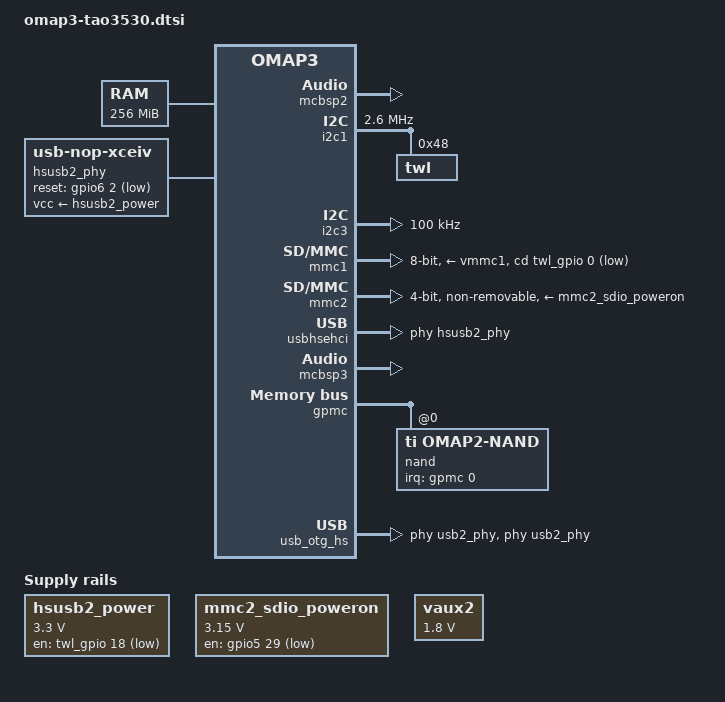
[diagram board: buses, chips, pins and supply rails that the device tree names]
/dts-v1/;
#include "omap34xx.dtsi"
&aes1_target {
	status = "disabled";
};
&aes2_target {
	status = "disabled";
};
&sham {
	status = "disabled";
};
/ {
	cpus {
		cpu@0 {
			cpu0-supply = <&vcc>;
		};
	};
	memory@80000000 {
		device_type = "memory";
		reg = <0x80000000 0x10000000>;  
	};
	hsusb2_power: hsusb2_power_reg {
		compatible = "regulator-fixed";
		regulator-name = "hsusb2_vbus";
		regulator-min-microvolt = <3300000>;
		regulator-max-microvolt = <3300000>;
		gpio = <&twl_gpio 18 GPIO_ACTIVE_HIGH>;	 
		startup-delay-us = <70000>;
	};
	hsusb2_phy: hsusb2-phy-pins {
		compatible = "usb-nop-xceiv";
		reset-gpios = <&gpio6 2 GPIO_ACTIVE_LOW>;	 
		vcc-supply = <&hsusb2_power>;
		#phy-cells = <0>;
	};
	sound {
		compatible = "ti,omap-twl4030";
		ti,model = "omap3beagle";
		ti,mcbsp = <&mcbsp2>;
	};
	mmc2_sdio_poweron: regulator-mmc2-sdio-poweron {
		compatible = "regulator-fixed";
		regulator-name = "regulator-mmc2-sdio-poweron";
		regulator-min-microvolt = <3150000>;
		regulator-max-microvolt = <3150000>;
		gpio = <&gpio5 29 GPIO_ACTIVE_LOW>;		 
		startup-delay-us = <10000>;
	};
};
&omap3_pmx_core {
	hsusbb2_pins: hsusbb2-pins {
		pinctrl-single,pins = <
			OMAP3_CORE1_IOPAD(0x25f0, PIN_OUTPUT | MUX_MODE3)		 
			OMAP3_CORE1_IOPAD(0x25f2, PIN_OUTPUT | MUX_MODE3)		 
			OMAP3_CORE1_IOPAD(0x25f4, PIN_INPUT_PULLDOWN | MUX_MODE3)	 
			OMAP3_CORE1_IOPAD(0x25f6, PIN_INPUT_PULLDOWN | MUX_MODE3)	 
			OMAP3_CORE1_IOPAD(0x25f8, PIN_INPUT_PULLDOWN | MUX_MODE3)	 
			OMAP3_CORE1_IOPAD(0x25fa, PIN_INPUT_PULLDOWN | MUX_MODE3)	 
			OMAP3_CORE1_IOPAD(0x21d4, PIN_INPUT_PULLDOWN | MUX_MODE3)	 
			OMAP3_CORE1_IOPAD(0x21d6, PIN_INPUT_PULLDOWN | MUX_MODE3)	 
			OMAP3_CORE1_IOPAD(0x21d8, PIN_INPUT_PULLDOWN | MUX_MODE3)	 
			OMAP3_CORE1_IOPAD(0x21da, PIN_INPUT_PULLDOWN | MUX_MODE3)	 
			OMAP3_CORE1_IOPAD(0x21dc, PIN_INPUT_PULLDOWN | MUX_MODE3)	 
			OMAP3_CORE1_IOPAD(0x21de, PIN_INPUT_PULLDOWN | MUX_MODE3)	 
		>;
	};
	mmc1_pins: mmc1-pins {
		pinctrl-single,pins = <
			OMAP3_CORE1_IOPAD(0x2144, PIN_INPUT_PULLUP | MUX_MODE0)	 
			OMAP3_CORE1_IOPAD(0x2146, PIN_INPUT_PULLUP | MUX_MODE0)	 
			OMAP3_CORE1_IOPAD(0x2148, PIN_INPUT_PULLUP | MUX_MODE0)	 
			OMAP3_CORE1_IOPAD(0x214a, PIN_INPUT_PULLUP | MUX_MODE0)	 
			OMAP3_CORE1_IOPAD(0x214c, PIN_INPUT_PULLUP | MUX_MODE0)	 
			OMAP3_CORE1_IOPAD(0x214e, PIN_INPUT_PULLUP | MUX_MODE0)	 
			OMAP3_CORE1_IOPAD(0x2150, PIN_INPUT_PULLUP | MUX_MODE0)  
			OMAP3_CORE1_IOPAD(0x2152, PIN_INPUT_PULLUP | MUX_MODE0)  
			OMAP3_CORE1_IOPAD(0x2154, PIN_INPUT_PULLUP | MUX_MODE0)  
			OMAP3_CORE1_IOPAD(0x2156, PIN_INPUT_PULLUP | MUX_MODE0)  
		>;
	};
	mmc2_pins: mmc2-pins {
		pinctrl-single,pins = <
			OMAP3_CORE1_IOPAD(0x2158, PIN_INPUT_PULLUP | MUX_MODE0)	 
			OMAP3_CORE1_IOPAD(0x215a, PIN_INPUT_PULLUP | MUX_MODE0)	 
			OMAP3_CORE1_IOPAD(0x215c, PIN_INPUT_PULLUP | MUX_MODE0)	 
			OMAP3_CORE1_IOPAD(0x215e, PIN_INPUT_PULLUP | MUX_MODE0)	 
			OMAP3_CORE1_IOPAD(0x2160, PIN_INPUT_PULLUP | MUX_MODE0)	 
			OMAP3_CORE1_IOPAD(0x2162, PIN_INPUT_PULLUP | MUX_MODE0)	 
		>;
	};
	wlan_gpio: wlan-gpio-pins {
		pinctrl-single,pins = <
			OMAP3_CORE1_IOPAD(0x218e, PIN_OUTPUT | MUX_MODE4)	 
		>;
	};
	uart3_pins: uart3-pins {
		pinctrl-single,pins = <
			OMAP3_CORE1_IOPAD(0x219e, PIN_INPUT | PIN_OFF_WAKEUPENABLE | MUX_MODE0)  
			OMAP3_CORE1_IOPAD(0x21a0, PIN_OUTPUT | MUX_MODE0)	 
		>;
	};
	i2c3_pins: i2c3-pins {
		pinctrl-single,pins = <
			OMAP3_CORE1_IOPAD(0x21c2, PIN_INPUT_PULLUP | MUX_MODE0)	 
			OMAP3_CORE1_IOPAD(0x21c4, PIN_INPUT_PULLUP | MUX_MODE0)	 
		>;
	};
	mcspi1_pins: mcspi1-pins {
		pinctrl-single,pins = <
			OMAP3_CORE1_IOPAD(0x21c8, PIN_INPUT | MUX_MODE0)	 
			OMAP3_CORE1_IOPAD(0x21ca, PIN_OUTPUT | MUX_MODE0)	 
			OMAP3_CORE1_IOPAD(0x21cc, PIN_INPUT_PULLUP | MUX_MODE0)	 
			OMAP3_CORE1_IOPAD(0x21ce, PIN_OUTPUT | MUX_MODE0)	 
		>;
	};
	mcspi3_pins: mcspi3-pins {
		pinctrl-single,pins = <
                        OMAP3_CORE1_IOPAD(0x25dc, PIN_OUTPUT | MUX_MODE1)	 
                        OMAP3_CORE1_IOPAD(0x25de, PIN_INPUT_PULLUP | MUX_MODE1)	 
                        OMAP3_CORE1_IOPAD(0x25e0, PIN_OUTPUT | MUX_MODE1)	 
                        OMAP3_CORE1_IOPAD(0x25e2, PIN_INPUT | MUX_MODE1)	 
		>;
	};
	mcbsp3_pins: mcbsp3-pins {
		pinctrl-single,pins = <
			OMAP3_CORE1_IOPAD(0x216c, PIN_OUTPUT | MUX_MODE0)	 
			OMAP3_CORE1_IOPAD(0x216e, PIN_INPUT | MUX_MODE0)	 
			OMAP3_CORE1_IOPAD(0x2170, PIN_INPUT | MUX_MODE0)	 
			OMAP3_CORE1_IOPAD(0x2172, PIN_INPUT | MUX_MODE0)	 
		>;
	};
};
&mcbsp1 {
	status = "disabled";
};
&mcbsp2 {
	status = "okay";
};
&i2c1 {
	clock-frequency = <2600000>;
	twl: twl@48 {
		reg = <0x48>;
		interrupts = <7>;  
		interrupt-parent = <&intc>;
		twl_audio: audio {
			compatible = "ti,twl4030-audio";
			codec {
			};
		};
	};
};
&i2c3 {
	clock-frequency = <100000>;
	pinctrl-names = "default";
	pinctrl-0 = <&i2c3_pins>;
};
&mcspi1 {
	pinctrl-names = "default";
	pinctrl-0 = <&mcspi1_pins>;
};
&mcspi3 {
	pinctrl-names = "default";
	pinctrl-0 = <&mcspi3_pins>;
};
#include "twl4030.dtsi"
#include "twl4030_omap3.dtsi"
&mmc1 {
	pinctrl-names = "default";
	pinctrl-0 = <&mmc1_pins>;
	vmmc-supply = <&vmmc1>;
	vqmmc-supply = <&vsim>;
	cd-gpios = <&twl_gpio 0 GPIO_ACTIVE_LOW>;
	bus-width = <8>;
};
&mmc2 {
	pinctrl-names = "default";
	pinctrl-0 = <&mmc2_pins>;
	vmmc-supply = <&mmc2_sdio_poweron>;
	non-removable;
	bus-width = <4>;
	cap-power-off-card;
};
&mmc3 {
	status = "disabled";
};
&usbhshost {
	port2-mode = "ehci-phy";
};
&usbhsehci {
	phys = <0 &hsusb2_phy>;
};
&twl_gpio {
	ti,use-leds;
	ti,pullups = <0x000002>;
	ti,pulldowns = <0x03a1c4>;
};
&uart3 {
	pinctrl-names = "default";
	pinctrl-0 = <&uart3_pins>;
};
&mcbsp3 {
	status = "okay";
	pinctrl-names = "default";
	pinctrl-0 = <&mcbsp3_pins>;
};
&gpmc {
	ranges = <0 0 0x30000000 0x01000000>;	 
	nand@0,0 {
		compatible = "ti,omap2-nand";
		reg = <0 0 4>;  
		interrupt-parent = <&gpmc>;
		interrupts = <0 IRQ_TYPE_NONE>,  
			     <1 IRQ_TYPE_NONE>;	 
		nand-bus-width = <16>;
		gpmc,device-width = <2>;	 
		ti,nand-ecc-opt = "sw";
		gpmc,cs-on-ns = <0>;
		gpmc,cs-rd-off-ns = <36>;
		gpmc,cs-wr-off-ns = <36>;
		gpmc,adv-on-ns = <6>;
		gpmc,adv-rd-off-ns = <24>;
		gpmc,adv-wr-off-ns = <36>;
		gpmc,oe-on-ns = <6>;
		gpmc,oe-off-ns = <48>;
		gpmc,we-on-ns = <6>;
		gpmc,we-off-ns = <30>;
		gpmc,rd-cycle-ns = <72>;
		gpmc,wr-cycle-ns = <72>;
		gpmc,access-ns = <54>;
		gpmc,wr-access-ns = <30>;
		#address-cells = <1>;
		#size-cells = <1>;
		x-loader@0 {
			label = "X-Loader";
			reg = <0 0x80000>;
		};
		bootloaders@80000 {
			label = "U-Boot";
			reg = <0x80000 0x1e0000>;
		};
		bootloaders_env@260000 {
			label = "U-Boot Env";
			reg = <0x260000 0x20000>;
		};
		kernel@280000 {
			label = "Kernel";
			reg = <0x280000 0x400000>;
		};
		filesystem@680000 {
			label = "File System";
			reg = <0x680000 0xf980000>;
		};
	};
};
&usb_otg_hs {
	interface-type = <0>;
	usb-phy = <&usb2_phy>;
	phys = <&usb2_phy>;
	phy-names = "usb2-phy";
	mode = <3>;
	power = <50>;
};
&vaux2 {
	regulator-name = "vdd_ehci";
	regulator-min-microvolt = <1800000>;
	regulator-max-microvolt = <1800000>;
	regulator-always-on;
};
